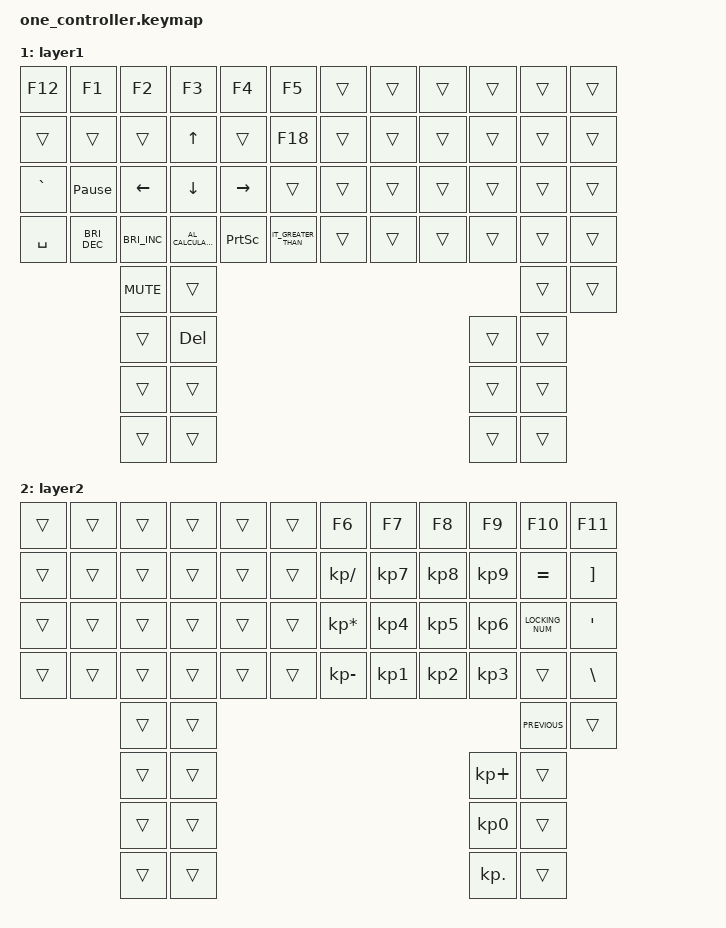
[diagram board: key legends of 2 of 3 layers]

  /*
  * Copyright (c) 2020 The ZMK Contributors
  *
  * SPDX-License-Identifier: MIT
  */

  #include <behaviors.dtsi>
  #include <dt-bindings/zmk/keys.h>
  #include <dt-bindings/zmk/bt.h>
  #include <dt-bindings/zmk/ext_power.h>
  #include "keys_it.h"

  / {
    keymap {
      compatible = "zmk,keymap";
  layer0 {
          bindings = <
            &kp ESCAPE &kp N1 &kp N2 &kp N3 &kp N4 &kp N5     &kp N6 &kp N7 &kp N8 &kp N9 &kp N0 &kp MINUS 
            &kp LEFT_ALT &kp Q &kp W &kp E &kp R &kp T        &kp Y &kp U &kp I &kp O &kp P &kp LEFT_BRACKET 
            &kp CAPSLOCK &kp A &kp S &kp D &kp F &kp G        &kp H &kp J &kp K &kp L &kp SEMICOLON &kp SINGLE_QUOTE 
            &kp TAB &kp Z &kp X &kp C &kp V &kp B             &kp N &kp M &kp COMMA &kp DOT &kp SLASH &kp BACKSLASH 

              &kp C_VOLUME_DOWN &kp C_VOLUME_UP                 &kp C_PLAY_PAUSE &kp C_NEXT 
                      &kp LEFT_GUI &kp BACKSPACE                          &kp SPACE &kp KP_ENTER 
                              &mo 1 &kp LEFT_ALT                               &kp LEFT_CONTROL  &kp LEFT_SHIFT 
                              &kp LEFT_CONTROL                                    &kp LEFT_SHIFT  &mo 2
          >;
        };layer1 {
          bindings = <
            &kp F12 &kp F1 &kp F2 &kp F3 &kp F4 &kp F5                                                              &trans &trans &trans &trans &trans &trans
            &trans &trans &trans &kp UP &trans &kp F18                                                              &trans &trans &trans &trans &trans &trans 
            &kp GRAVE &kp PAUSE_BREAK &kp LEFT &kp DOWN &kp RIGHT                                                   &trans &trans &trans &trans &trans &trans &trans 
            &kp SPACE &kp C_BRIGHTNESS_DEC &kp C_BRIGHTNESS_INC &kp C_AL_CALCULATOR &kp PRINTSCREEN &kp IT_GREATER_THAN          &trans &trans &trans &trans &trans &trans 

                &kp C_MUTE &trans                                                                                       &trans &trans 
                        &trans &kp DELETE                                                                                       &trans &trans 
                                &trans &trans                                                                                   &trans &trans 
                                &trans &trans                                                                                   &trans &trans
          >;
        };layer2 {
          bindings = <
          &trans &trans &trans &trans &trans &trans     &kp F6 &kp F7 &kp F8 &kp F9 &kp F10 &kp F11 
          &trans &trans &trans &trans &trans &trans     &kp KP_SLASH &kp KP_N7 &kp KP_N8 &kp KP_N9 &kp EQUAL &kp RIGHT_BRACKET 
          &trans &trans &trans &trans &trans &trans     &kp KP_ASTERISK &kp KP_N4 &kp KP_N5 &kp KP_N6 &kp LOCKING_NUM &kp SINGLE_QUOTE 
          &trans &trans &trans &trans &trans &trans     &kp KP_MINUS &kp KP_N1 &kp KP_N2 &kp KP_N3 &trans &kp BACKSLASH 
                        &trans &trans                                       &kp C_PREVIOUS &trans 
                        &trans &trans                                       &kp KP_PLUS &trans 
                        &trans &trans                                       &kp KP_N0 &trans 
                        &trans &trans                                       &kp KP_DOT &trans
          >;
        };extra1 {
            status = "reserved";
        };

        extra2 {
            status = "reserved";
        };
    };
  };
  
